# psoc6a2m register map
Vendor: Cypress Semiconductor; Series: psoc6a2m; File version: 1.0
CPU: CM4 r0p1, little endian, MPU, FPU, VTOR, 3 interrupt priority bits
Registers are 32-bit, read-write, reset 0x0 unless marked. A register's access mark holds for its fields unless they carry their own. Offsets are from the block's base; [hi:lo] are bit positions; lines under a group give offsets from that group; {n}, {i} and the like mark numbered series; 'fields as' and 'values as' point back to an identical list; <NAME> marks a mode.

## SRSS — SRSS Core Registers
Base 0x40260000
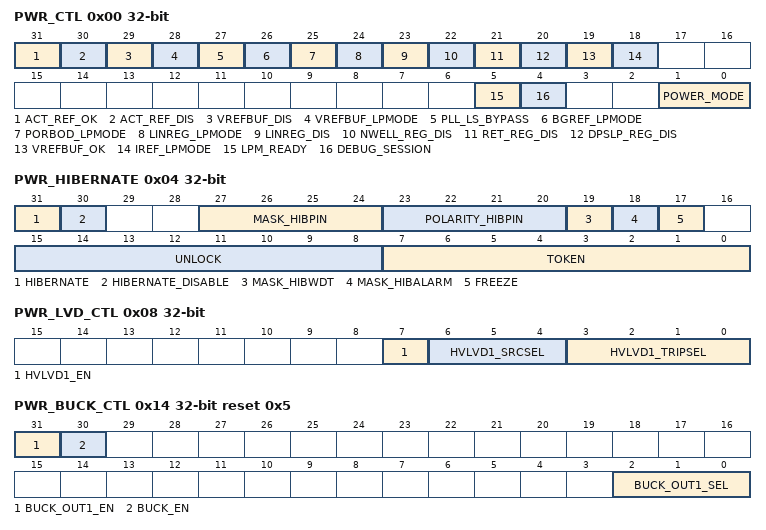
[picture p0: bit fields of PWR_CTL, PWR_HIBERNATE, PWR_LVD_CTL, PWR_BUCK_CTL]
0x00 PWR_CTL — Power Mode Control
  [31] ACT_REF_OK ro — Indicates that the normal mode of the Active Reference is ready.
  [30] ACT_REF_DIS — Disables the Active Reference. Firmware must ensure that LPM_READY==1 and BGREF_LPMODE==1 for at least 1us before disabling the Active Reference. When enabling the Active Reference, use ACT_REF_OK indicator to know when it is ready. This register is only reset by XRES/POR/BOD/OVP/HIBERNATE. 0: Active Reference is enabled 1: Active Reference is disabled
  [29] VREFBUF_DIS — Disable the 800mV voltage reference buffer. Firmware should only disable the buffer when there is no connected circuit that is using it. SRSS circuits that require it are the PLL and ECO. A particular product may have circuits outside the SRSS that use the buffer. This register is only reset by XRES/POR/BOD/OVP/HIBERNATE.
  [28] VREFBUF_LPMODE — Control the power mode of the 800mV voltage reference buffer. The value in this register is ignored and normal mode is used until LPM_READY==1. 0: ULP Voltage Reference Buffer operates in normal mode. They work for vddd ramp rates of 100mV/us or less. This register is only reset by XRES/POR/BOD/OVP/HIBERNATE. 1: ULP Voltage Reference Buffer operates in low power mode. Power supply rejection is reduced to save current, and they work for vddd ramp rates of 10mV/us or less.
  [27] PLL_LS_BYPASS — Bypass level shifter inside the PLL. 0: Do not bypass the level shifter. This setting is ok for all operational modes and vccd target voltage. 1: Bypass the level shifter. This may reduce jitter on the PLL output clock, but can only be used when vccd is targeted to 1.1V nominal. Otherwise, it can result in clock degradation and static current.
  [26] BGREF_LPMODE — Control the power mode of the ULP Bandgap Voltage and Current References. This applies to voltage and current generation and is different than the reference voltage buffer. The value in this register is ignored and normal mode is used until LPM_READY==1. When lower power mode is used, the Active Reference circuit can be disabled to reduce current. Firmware is responsible to ensure ACT_REF_OK==1 before changing back to normal mode. This register is only reset by XRES/POR/BOD/OVP/HIBERNATE. 0: ULP Active Bandgap Voltage and Current Reference operates in normal mode. They work for vddd ramp rates of 100mV/us or less. 1: ULP Active Bandgap Voltage and Current Reference operates in low power mode. Power supply rejection is reduced to save current, and they work for vddd ramp rates of 10mV/us or less. The Active Reference may be disabled using ACT_REF_DIS=0.
  [25] PORBOD_LPMODE — Control the power mode of the ULP POR/BOD circuits. The value in this register is ignored and normal mode is used until LPM_READY==1. This register is only reset by XRES/POR/BOD/OVP/HIBERNATE. 0: ULP POR/BOD circuits operate in normal mode. They work for vddd ramp rates of 100mV/us or less. 1: ULP POR/BOD circuits operate in low power mode. Response time is reduced to save current, and they work for vddd ramp rates of 10mV/us or less.
  [24] LINREG_LPMODE — Control the power mode of the ULP Linear Regulator. The value in this register is ignored and normal mode is used until LPM_READY==1. This register is only reset by XRES/POR/BOD/OVP/HIBERNATE. 0: ULP Linear Regulator operates in normal mode. Internal current consumption is 50uA and load current capability is 50mA to 300mA, depending on the number of regulator modules present in the product. 1: ULP Linear Regulator operates in low power mode. Internal current consumption is 5uA and load current capability is 25mA. Firmware must ensure the current is kept within the limit.
  [23] LINREG_DIS — Disable the linear Core Regulator. For ULP products, this is only legal when the ULP SISO-LC/SIMO-LC Buck supplies vccd, but there is no hardware protection for this case. This register is only reset by XRES/POR/BOD/OVP/HIBERNATE. 0: Linear regulator is on. 1: Linear regulator is off.
  [22] NWELL_REG_DIS — Disable the Nwell regulator. For ULP products, this is only legal when the ULP SISO-LC/SIMO-LC Buck supplies vccd, but there is no hardware protection for this case. This register is only reset by XRES/POR/BOD/OVP/HIBERNATE. 0: Nwell Regulator is on. 1: Nwell Regulator is off.
  [21] RET_REG_DIS — Disable the Retention regulator. For ULP products, this is only legal when the ULP SISO-LC/SIMO-LC Buck supplies vccd, but there is no hardware protection for this case. This register is only reset by XRES/POR/BOD/OVP/HIBERNATE. 0: Retention Regulator is on. 1: Retention Regulator is off.
  [20] DPSLP_REG_DIS — Disable the DeepSleep regulator. For ULP products, this is only legal when the ULP SISO-LC/SIMO-LC Buck supplies vccd, but there is no hardware protection for this case. This register is only reset by XRES/POR/BOD/OVP/HIBERNATE. 0: DeepSleep Regulator is on. 1: DeepSleep Regulator is off.
  [19] VREFBUF_OK ro — Indicates that the voltage reference buffer is ready. Due to synchronization delays, it may take two IMO clock cycles for hardware to clear this bit after asserting VREFBUF_DIS=1.
  [18] IREF_LPMODE — Control the power mode of the reference current generator. The value in this register is ignored and normal mode is used until LPM_READY==1. This register is only reset by XRES/POR/BOD/OVP/HIBERNATE. 0: Current reference generator operates in normal mode. It works for vddd ramp rates of 100mV/us or less. 1: Current reference generator operates in low power mode. Response time is reduced to save current, and it works for vddd ramp rates of 10mV/us or less.
  [5] LPM_READY ro — Indicates whether certain low power functions are ready. The low current circuits take longer to startup after POR/XRES/BOD/HIBERNATE wakeup than the normal mode circuits. HIBERNATE mode may be entered regardless of this bit. This register is only reset by XRES/POR/BOD/OVP/HIBERNATE. 0: If a low power circuit operation is requested, it will stay in its normal operating mode until it is ready. If DEEPSLEEP is requested by all processors WFI/WFE, the device will instead enter SLEEP. When low power circuits are ready, device will automatically enter the originally requested mode. 1: Normal operation. DEEPSLEEP and low power circuits operate as requested in other registers.
  [4] DEBUG_SESSION ro — Indicates whether a debug session is active (CDBGPWRUPREQ signal is 1)
    0=NO_SESSION (No debug session active); 1=SESSION_ACTIVE (Debug session is active. Power modes behave differently to keep the debug session active.)
  [1:0] POWER_MODE ro — Current power mode of the device. LPACTIVE/LPSLEEP are implemented as firmware configuration of multiple registers and are reported here as ACTIVE/SLEEP, respectively. Note that this field cannot be read in all power modes on actual silicon.
    0=RESET (System is resetting.); 1=ACTIVE (At least one CPU is running.); 2=SLEEP (No CPUs are running. Peripherals may be running.); 3=DEEPSLEEP (Main high-frequency clock is off; low speed clocks are available. Communication interface clocks may be present.)
0x04 PWR_HIBERNATE — HIBERNATE Mode Register
  [31] HIBERNATE — Firmware sets this bit to enter HIBERNATE mode. The system will enter HIBERNATE mode immediately after writing to this bit and will wakeup only in response to XRES or WAKEUP event. Both UNLOCK and FREEZE must have been set correctly in a previous write operations. Otherwise, it will not enter HIBERNATE. External supplies must have been stable for 250us before entering HIBERNATE mode.
  [30] HIBERNATE_DISABLE — Hibernate disable bit. 0: Normal operation, HIBERNATE works as described 1: Further writes to this register are ignored Note: This bit is a write-once bit until the next reset. Avoid changing any other bits in this register while disabling HIBERNATE mode. Also, it is recommended to clear the UNLOCK code, if it was previously written..
  [27:24] MASK_HIBPIN — When set, HIBERNATE will wakeup if the corresponding pin input matches the POLARITY_HIBPIN setting. Each bit corresponds to one of the wakeup pins.
  [23:20] POLARITY_HIBPIN — Each bit sets the active polarity of the corresponding wakeup pin. 0: Pin input of 0 will wakeup the part from HIBERNATE 1: Pin input of 1 will wakeup the part from HIBERNATE
  [19] MASK_HIBWDT — When set, HIBERNATE will wakeup if WDT matches
  [18] MASK_HIBALARM — When set, HIBERNATE will wakeup for a RTC interrupt
  [17] FREEZE — Firmware sets this bit to freeze the configuration, mode and state of all GPIOs and SIOs in the system. When entering HIBERNATE mode, the first write instructs DEEPSLEEP peripherals that they cannot ignore the upcoming freeze command. This occurs even in the illegal condition where UNLOCK is not set. If UNLOCK and HIBERNATE are properly set, the IOs actually freeze on the second write.
  [15:8] UNLOCK — This byte must be set to 0x3A for FREEZE or HIBERNATE fields to operate. Any other value in this register will cause FREEZE/HIBERNATE to have no effect, except as noted in the FREEZE description.
  [7:0] TOKEN — Contains a 8-bit token that is retained through a HIBERNATE/WAKEUP sequence that can be used by firmware to differentiate WAKEUP from a general RESET event. Note that waking up from HIBERNATE using XRES will reset this register.
0x08 PWR_LVD_CTL — Low Voltage Detector (LVD) Configuration Register
  [7] HVLVD1_EN — Enable HVLVD1 voltage monitor. When the LVD is enabled, it takes 20us for it to settle. There is no hardware stabilization counter, and it may falsely trigger during settling. It is recommended that firmware keep the interrupt masked for at least 8us, write a 1'b1 to the corresponding SRSS_INTR field to any falsely pended interrupt, and then optionally unmask the interrupt. After enabling, it further recommended to read the realted PWR_LVD_STATUS field, since the interrupt only triggers on edges. This bit is cleared (LVD is disabled) when entering DEEPSLEEP to prevent false interrupts during wakeup.
  [6:4] HVLVD1_SRCSEL — Source selection for HVLVD1
    0=VDDD (Select VDDD); 1=AMUXBUSA (Select AMUXBUSA (VDDD branch)); 2=RSVD (N/A); 3=VDDIO (N/A); 4=AMUXBUSB (Select AMUXBUSB (VDDD branch))
  [3:0] HVLVD1_TRIPSEL — Threshold selection for HVLVD1. Disable the LVD (HVLVD1_EN=0) before changing the threshold. 0: rise=1.225V (nom), fall=1.2V (nom) 1: rise=1.425V (nom), fall=1.4V (nom) 2: rise=1.625V (nom), fall=1.6V (nom) 3: rise=1.825V (nom), fall=1.8V (nom) 4: rise=2.025V (nom), fall=2V (nom) 5: rise=2.125V (nom), fall=2.1V (nom) 6: rise=2.225V (nom), fall=2.2V (nom) 7: rise=2.325V (nom), fall=2.3V (nom) 8: rise=2.425V (nom), fall=2.4V (nom) 9: rise=2.525V (nom), fall=2.5V (nom) 10: rise=2.625V (nom), fall=2.6V (nom) 11: rise=2.725V (nom), fall=2.7V (nom) 12: rise=2.825V (nom), fall=2.8V (nom) 13: rise=2.925V (nom), fall=2.9V (nom) 14: rise=3.025V (nom), fall=3.0V (nom) 15: rise=3.125V (nom), fall=3.1V (nom)
0x14 PWR_BUCK_CTL reset 0x5 — Buck Control Register
  [31] BUCK_OUT1_EN — Enable for vccbuck1 output. The value in this register is ignored unless PWR_BUCK_CTL.BUCK_EN==1. This register is only reset by XRES/POR/BOD/OVP/HIBERNATE. The regulator takes up to 600us to charge the external capacitor. If there is additional load current while charging, this will increase the startup time. The SAS specifies the required sequence when transitioning vccd from the LDO to SIMO Buck output #1.
  [30] BUCK_EN — Master enable for buck converter. This register is only reset by XRES/POR/BOD/OVP/HIBERNATE.
  [2:0] BUCK_OUT1_SEL — Voltage output selection for vccbuck1 output. This register is only reset by XRES/POR/BOD/OVP/HIBERNATE. When increasing the voltage, it can take up to 200us for the output voltage to settle. When decreasing the voltage, the settling time depends on the load current. 0: 0.85V 1: 0.875V 2: 0.90V 3: 0.95V 4: 1.05V 5: 1.10V 6: 1.15V 7: 1.20V
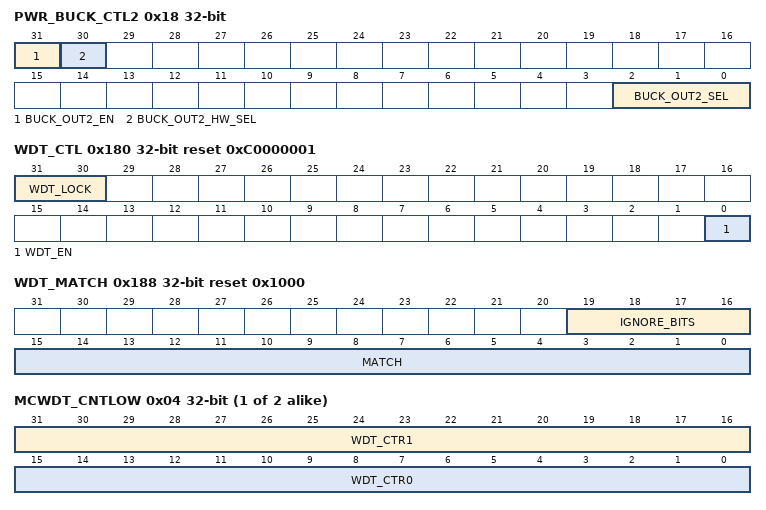
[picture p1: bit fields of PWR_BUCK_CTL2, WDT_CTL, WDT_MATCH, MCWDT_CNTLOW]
0x18 PWR_BUCK_CTL2 — Buck Control Register 2
  [31] BUCK_OUT2_EN — Enable for vccbuck2 output. The value in this register is ignored unless PWR_BUCK_CTL.BUCK_EN==1. The regulator takes up to 600us to charge the external capacitor. If there is additional load current while charging, this will increase the startup time.
  [30] BUCK_OUT2_HW_SEL — Hardware control for vccbuck2 output. When this bit is set, the value in BUCK_OUT2_EN is ignored and a hardware signal is used instead. If the product has supporting hardware, it can directly control the enable signal for vccbuck2. The same charging time in BUCK_OUT2_EN applies.
  [2:0] BUCK_OUT2_SEL — Voltage output selection for vccbuck2 output. When increasing the voltage, it can take up to 200us for the output voltage to settle. When decreasing the voltage, the settling time depends on the load current. 0: 1.15V 1: 1.20V 2: 1.25V 3: 1.30V 4: 1.35V 5: 1.40V 6: 1.45V 7: 1.50V
0x1C PWR_LVD_STATUS ro — Low Voltage Detector (LVD) Status Register
  [0] HVLVD1_OK — HVLVD1 output. 0: below voltage threshold 1: above voltage threshold
{0x80+4i} PWR_HIB_DATA[{i}] (i=0..15) — HIBERNATE Data Register
  [31:0] HIB_DATA — Additional data that is retained through a HIBERNATE/WAKEUP sequence that can be used by firmware for any application-specific purpose. Note that waking up from HIBERNATE using XRES will reset this register.
0x180 WDT_CTL reset 0xC0000001 — Watchdog Counter Control Register
  [31:30] WDT_LOCK — Prohibits writing to WDT_*, CLK_ILO_CONFIG, CLK_SELECT.LFCLK_SEL, and CLK_TRIM_ILO_CTL registers when not equal 0. Requires at least two different writes to unlock. A change in WDT_LOCK takes effect beginning with the next write cycle. Note that this field is 2 bits to force multiple writes only. It represents only a single write protect signal protecting all those registers at the same time. WDT will lock on any reset. This field is not retained during DEEPSLEEP or HIBERNATE mode, so the WDT will be locked after wakeup from these modes.
    0=NO_CHG (No effect); 1=CLR0 (Clears bit 0); 2=CLR1 (Clears bit 1); 3=SET01 (Sets both bits 0 and 1)
  [0] WDT_EN — Enable this watchdog timer. This field is retained during DEEPSLEEP and HIBERNATE modes.
0x184 WDT_CNT — Watchdog Counter Count Register
  [15:0] COUNTER — Current value of WDT Counter. The write feature of this register is for engineering use (DfV), have no synchronization, and can only be applied when the WDT is fully off. When writing, the value is updated immediately in the WDT counter, but it will read back as the old value until this register resynchronizes just after the negedge of ILO. Writes will be ignored if they occur when the WDT is enabled.
0x188 WDT_MATCH reset 0x1000 — Watchdog Counter Match Register
  [19:16] IGNORE_BITS — The number of MSB bits of the watchdog timer that are NOT checked against MATCH. This value provides control over the time-to-reset of the watchdog (which happens after 3 successive matches). Up to 12 MSB can be ignored. Settings >12 behave like a setting of 12.
  [15:0] MATCH — Match value for Watchdog counter. Every time WDT_COUNTER reaches MATCH an interrupt is generated. Two unserviced interrupts will lead to a system reset (i.e. at the third match).
{0x200+0x40*i} MCWDT_STRUCT[{i}] (i=0..1) group — Multi-Counter Watchdog Timer
  0x04 MCWDT_CNTLOW — Multi-Counter Watchdog Sub-counters 0/1
    [31:16] WDT_CTR1 — Current value of sub-counter 1 for this MCWDT. Software writes are ignored when the sub-counter is enabled
    [15:0] WDT_CTR0 — Current value of sub-counter 0 for this MCWDT. Software writes are ignored when the sub-counter is enabled.
  0x08 MCWDT_CNTHIGH — Multi-Counter Watchdog Sub-counter 2
    [31:0] WDT_CTR2 — Current value of sub-counter 2 for this MCWDT. Software writes are ignored when the sub-counter is enabled
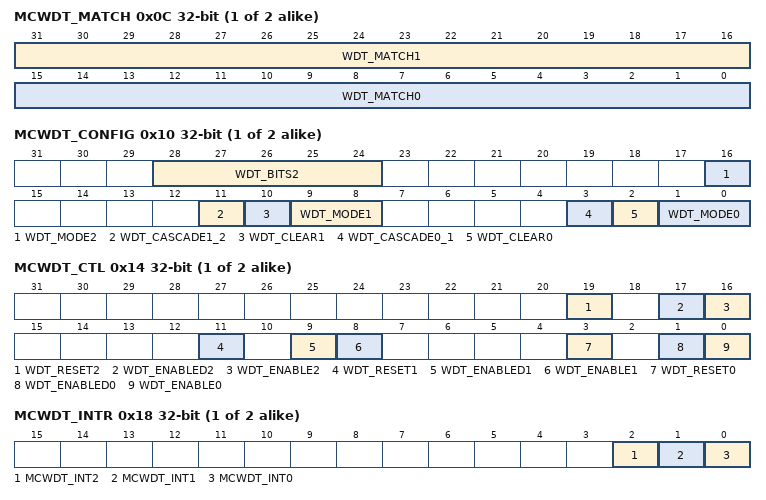
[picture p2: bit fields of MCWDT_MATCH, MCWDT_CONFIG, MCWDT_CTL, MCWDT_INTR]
  0x0C MCWDT_MATCH — Multi-Counter Watchdog Counter Match Register
    [31:16] WDT_MATCH1 — Match value for sub-counter 1 of this MCWDT
    [15:0] WDT_MATCH0 — Match value for sub-counter 0 of this MCWDT
  0x10 MCWDT_CONFIG — Multi-Counter Watchdog Counter Configuration
    [28:24] WDT_BITS2 — Bit to observe for WDT_INT2: 0: Assert after bit0 of WDT_CTR2 toggles (one int every tick) .. 31: Assert after bit31 of WDT_CTR2 toggles (one int every 2^31 ticks)
    [16] WDT_MODE2 — Watchdog Counter 2 Mode.
      0=NOTHING (Free running counter with no interrupt requests); 1=INT (Free running counter with interrupt request that occurs one LFCLK cycle after the specified bit in CTR2 toggles (see WDT_BITS2).)
    [11] WDT_CASCADE1_2 — Cascade Watchdog Counters 1,2. Counter 2 increments the cycle after WDT_CTR1=WDT_MATCH1. It is allowed to cascade all three WDT counters. 0: Independent counters 1: Cascaded counters. When cascading all three counters, WDT_CLEAR1 must be 1.
    [10] WDT_CLEAR1 — Clear Watchdog Counter when WDT_CTR1==WDT_MATCH1. In other words WDT_CTR1 divides LFCLK by (WDT_MATCH1+1). 0: Free running counter 1: Clear on match. In this mode, the minimum legal setting of WDT_MATCH1 is 1.
    [9:8] WDT_MODE1 — Watchdog Counter Action on Match. Action is taken on the next increment after the values match (WDT_CTR1=WDT_MATCH1).
      0=NOTHING (Do nothing); 1=INT (Assert WDT_INTx); 2=RESET (Assert WDT Reset); 3=INT_THEN_RESET (Assert WDT_INTx, assert WDT Reset after 3rd unhandled interrupt)
    [3] WDT_CASCADE0_1 — Cascade Watchdog Counters 0,1. Counter 1 increments the cycle after WDT_CTR0=WDT_MATCH0. 0: Independent counters 1: Cascaded counters
    [2] WDT_CLEAR0 — Clear Watchdog Counter when WDT_CTR0=WDT_MATCH0. In other words WDT_CTR0 divides LFCLK by (WDT_MATCH0+1). 0: Free running counter 1: Clear on match. In this mode, the minimum legal setting of WDT_MATCH0 is 1.
    [1:0] WDT_MODE0 — Watchdog Counter Action on Match. Action is taken on the next increment after the values match (WDT_CTR0=WDT_MATCH0).
      values as WDT_MODE1
  0x14 MCWDT_CTL — Multi-Counter Watchdog Counter Control
    [19] WDT_RESET2 — Resets counter 0 back to 0000. Hardware will reset this bit after counter was reset. This will take up to one LFCLK cycle to take effect.
    [17] WDT_ENABLED2 ro — Indicates actual state of counter. May lag WDT_ENABLE2 by up to two LFCLK cycles.
    [16] WDT_ENABLE2 — Enable subcounter 2. May take up to 2 LFCLK cycles to take effect. 0: Counter is disabled (not clocked) 1: Counter is enabled (counting up)
    [11] WDT_RESET1 — Resets counter 0 back to 0000. Hardware will reset this bit after counter was reset. This will take up to one LFCLK cycle to take effect.
    [9] WDT_ENABLED1 ro — Indicates actual state of counter. May lag WDT_ENABLE1 by up to two LFCLK cycles.
    [8] WDT_ENABLE1 — Enable subcounter 1. May take up to 2 LFCLK cycles to take effect. 0: Counter is disabled (not clocked) 1: Counter is enabled (counting up)
    [3] WDT_RESET0 — Resets counter 0 back to 0000. Hardware will reset this bit after counter was reset. This will take up to one LFCLK cycle to take effect.
    [1] WDT_ENABLED0 ro — Indicates actual state of counter. May lag WDT_ENABLE0 by up to two LFCLK cycles.
    [0] WDT_ENABLE0 — Enable subcounter 0. May take up to 2 LFCLK cycles to take effect. 0: Counter is disabled (not clocked) 1: Counter is enabled (counting up)
  0x18 MCWDT_INTR — Multi-Counter Watchdog Counter Interrupt Register
    [2] MCWDT_INT2 — MCWDT Interrupt Request for sub-counter 2. This bit is set by hardware as configured by this registers. This bit must be cleared by firmware. Clearing this bit also prevents Reset from happening when WDT_MODE2=3.
    [1] MCWDT_INT1 — MCWDT Interrupt Request for sub-counter 1. This bit is set by hardware as configured by this registers. This bit must be cleared by firmware. Clearing this bit also prevents Reset from happening when WDT_MODE1=3.
    [0] MCWDT_INT0 — MCWDT Interrupt Request for sub-counter 0. This bit is set by hardware as configured by this registers. This bit must be cleared by firmware. Clearing this bit also prevents Reset from happening when WDT_MODE0=3.
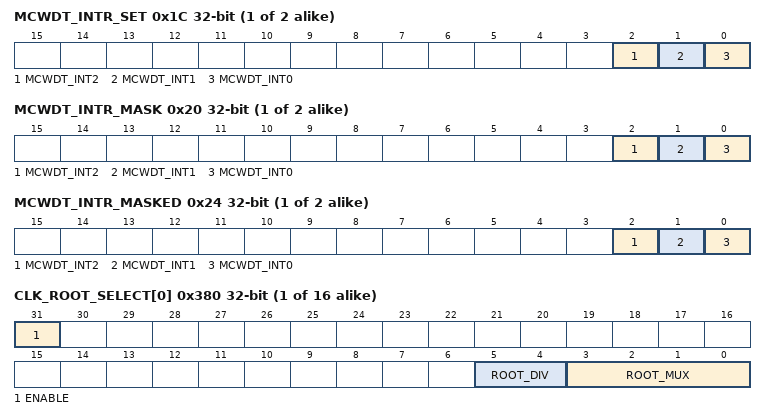
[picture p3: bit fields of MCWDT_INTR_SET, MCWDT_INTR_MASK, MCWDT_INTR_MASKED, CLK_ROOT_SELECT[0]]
  0x1C MCWDT_INTR_SET — Multi-Counter Watchdog Counter Interrupt Set Register
    [2] MCWDT_INT2 — Set interrupt for MCWDT_INT2
    [1] MCWDT_INT1 — Set interrupt for MCWDT_INT1
    [0] MCWDT_INT0 — Set interrupt for MCWDT_INT0
  0x20 MCWDT_INTR_MASK — Multi-Counter Watchdog Counter Interrupt Mask Register
    [2] MCWDT_INT2 — Mask for sub-counter 2
    [1] MCWDT_INT1 — Mask for sub-counter 1
    [0] MCWDT_INT0 — Mask for sub-counter 0
  0x24 MCWDT_INTR_MASKED ro — Multi-Counter Watchdog Counter Interrupt Masked Register
    [2] MCWDT_INT2 — Logical and of corresponding request and mask bits.
    [1] MCWDT_INT1 — Logical and of corresponding request and mask bits.
    [0] MCWDT_INT0 — Logical and of corresponding request and mask bits.
  0x28 MCWDT_LOCK — Multi-Counter Watchdog Counter Lock Register
    [31:30] MCWDT_LOCK — Prohibits writing control and configuration registers related to this MCWDT when not equal 0 (as specified in the other register descriptions). Requires at least two different writes to unlock. Note that this field is 2 bits to force multiple writes only. Each MCWDT has a separate local lock. LFCLK settings are locked by the global WDT_LOCK register, and this register has no effect on that.
      values as WDT_CTL.WDT_LOCK
{0x300+4i} CLK_DSI_SELECT[{i}] (i=0..15) — Clock DSI Select Register
  [4:0] DSI_MUX — Selects a DSI source or low frequency clock for use in a clock path. The output of this mux can be selected for clock PATH<i> using CLK_SELECT_PATH register. Using the output of this mux as HFCLK source will result in undefined behavior. It can be used to clocks to DSI or to the reference inputs of FLL/PLL, subject to the frequency limits of those circuits. This mux is not glitch free, so do not change the selection while it is an actively selected clock.
    {v}=DSI_OUT{v} (DSI{v} - dsi_out[{v}]) (v=0..15); 16=ILO (ILO - Internal Low-speed Oscillator); 17=WCO (WCO - Watch-Crystal Oscillator); 18=ALTLF (ALTLF - Alternate Low-Frequency Clock); 19=PILO (PILO - Precision Internal Low-speed Oscillator)
{0x340+4i} CLK_PATH_SELECT[{i}] (i=0..15) — Clock Path Select Register
  [2:0] PATH_MUX — Selects a source for clock PATH<i>. Note that not all products support all clock sources. Selecting a clock source that is not supported will result in undefined behavior.
    0=IMO (IMO - Internal R/C Oscillator); 1=EXTCLK (EXTCLK - External Clock Pin); 2=ECO (ECO - External-Crystal Oscillator); 3=ALTHF (ALTHF - Alternate High-Frequency clock input (product-specific clock)); 4=DSI_MUX (DSI_MUX - Output of DSI mux for this path. Using a DSI source directly as root of HFCLK will result in undefined behavior.)
{0x380+4i} CLK_ROOT_SELECT[{i}] (i=0..15) — Clock Root Select Register
  [31] ENABLE — Enable for this clock root. All clock roots default to disabled (ENABLE==0) except HFCLK0, which cannot be disabled.
  [5:4] ROOT_DIV — Selects predivider value for this clock root and DSI input.
    0=NO_DIV (Transparent mode, feed through selected clock source w/o dividing.); 1=DIV_BY_2 (Divide selected clock source by 2); 2=DIV_BY_4 (Divide selected clock source by 4); 3=DIV_BY_8 (Divide selected clock source by 8)
  [3:0] ROOT_MUX — Selects a clock path as the root of HFCLK<k> and for SRSS DSI input <k>. Use CLK_SELECT_PATH[i] to configure the desired path. Some paths may have FLL or PLL available (product-specific), and the control and bypass mux selections of these are in other registers. Configure the FLL using CLK_FLL_CONFIG register. Configure a PLL using the related CLK_PLL_CONFIG[k] register. Note that not all products support all clock sources. Selecting a clock source that is not supported will result in undefined behavior.
    0=PATH0 (Select PATH0 (can be configured for FLL)); {v}=PATH{v} (Select PATH{v} (can be configured for PLL{v-1}, if available in the product)) (v=1..15)
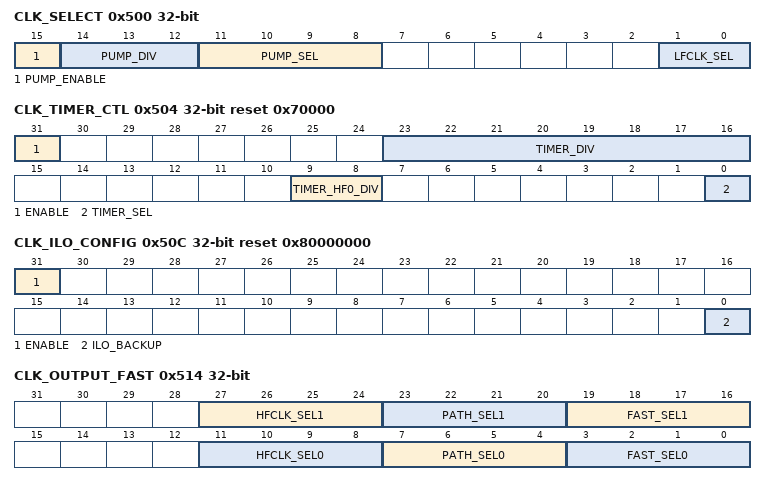
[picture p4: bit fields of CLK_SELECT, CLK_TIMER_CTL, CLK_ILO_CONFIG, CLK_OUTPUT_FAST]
0x500 CLK_SELECT — Clock selection register
  [15] PUMP_ENABLE — Enable the pump clock. PUMP_ENABLE and the PUMP_SEL mux are not glitch-free to minimize side-effects, avoid changing the PUMP_SEL and PUMP_DIV while changing PUMP_ENABLE. To change the settings, do the following: 1) If the pump clock is enabled, write PUMP_ENABLE=0 without changing PUMP_SEL and PUMP_DIV. 2) Change PUMP_SEL and PUMP_DIV to desired settings with PUMP_ENABLE=0. 3) Write PUMP_ENABLE=1 without changing PUMP_SEL and PUMP_DIV.
  [14:12] PUMP_DIV — Division ratio for PUMPCLK. Uses selected PUMP_SEL clock as the source.
    0=NO_DIV (Transparent mode, feed through selected clock source w/o dividing.); 1=DIV_BY_2 (Divide selected clock source by 2); 2=DIV_BY_4 (Divide selected clock source by 4); 3=DIV_BY_8 (Divide selected clock source by 8); 4=DIV_BY_16 (Divide selected clock source by 16)
  [11:8] PUMP_SEL — Selects clock PATH<k>, where k=PUMP_SEL. The output of this mux goes to the PUMP_DIV to make PUMPCLK Each product has a specific number of available clock paths. Selecting a path that is not implemented on a product will result in undefined behavior. Note that this is not a glitch free mux.
  [1:0] LFCLK_SEL — Select source for LFCLK. Note that not all products support all clock sources. Selecting a clock source that is not supported will result in undefined behavior. Writes to this field are ignored unless the WDT is unlocked using WDT_LOCK register.
    0=ILO (ILO - Internal Low-speed Oscillator); 1=WCO (WCO - Watch-Crystal Oscillator. Requires Backup domain to be present and properly configured (including external watch crystal, if used).); 2=ALTLF (ALTLF - Alternate Low-Frequency Clock. Capability is product-specific); 3=PILO (PILO - Precision ILO. If present, it works in DEEPSLEEP and higher modes. Does not work in HIBERNATE mode.)
0x504 CLK_TIMER_CTL reset 0x70000 — Timer Clock Control Register
  [31] ENABLE — Enable for TIMERCLK. 0: TIMERCLK is off 1: TIMERCLK is enabled
  [23:16] TIMER_DIV — Divide selected timer clock source by (1+TIMER_DIV). The output of this divider is TIMERCLK Allows for integer divisions in the range [1, 256]. Do not change this setting while the timer is enabled.
  [9:8] TIMER_HF0_DIV — Predivider used when HF0_DIV is selected in TIMER_SEL. If HFCLK0 frequency is less than 100MHz and has approximately 50 percent duty cycle, then no division is required (NO_DIV). Otherwise, select a divide ratio of 2, 4, or 8 before selected HF0_DIV as the timer clock.
    0=NO_DIV (Transparent mode, feed through selected clock source w/o dividing or correcting duty cycle.); 1=DIV_BY_2 (Divide HFCLK0 by 2.); 2=DIV_BY_4 (Divide HFCLK0 by 4.); 3=DIV_BY_8 (Divide HFCLK0 by 8.)
  [0] TIMER_SEL — Select source for TIMERCLK. The output of this mux can be further divided using TIMER_DIV.
    0=IMO (IMO - Internal Main Oscillator); 1=HF0_DIV (Select the output of the predivider configured by TIMER_HF0_DIV.)
0x50C CLK_ILO_CONFIG reset 0x80000000 — ILO Configuration
  [31] ENABLE — Master enable for ILO. Writes to this field are ignored unless the WDT is unlocked using WDT_LOCK register.
  [0] ILO_BACKUP — If backup domain is present on this product, this register indicates that ILO should stay enabled for use by backup domain during XRES, HIBERNATE mode, and through power-related resets like BOD on VDDD/VCCD. Writes to this field are ignored unless the WDT is unlocked using WDT_LOCK register. 0: ILO turns off at XRES/BOD event or HIBERNATE entry. 1: ILO remains on if backup domain is present and powered even for XRES/BOD or HIBERNATE entry.
0x510 CLK_IMO_CONFIG reset 0x80000000 — IMO Configuration
  [31] ENABLE — Master enable for IMO oscillator. This bit must be high at all times for all functions to work properly. Hardware will automatically disable the IMO during DEEPSLEEP, HIBERNATE, and XRES.
0x514 CLK_OUTPUT_FAST — Fast Clock Output Select Register
  [27:24] HFCLK_SEL1 — Selects a HFCLK tree for use in fast clock output #1 logic
  [23:20] PATH_SEL1 — Selects a clock path to use in fast clock output #1 logic. For FLL path, it connects after the bypass mux. For PLL path(s), it connects after the CLK_PLL_DDFT mux. 1-15: PLL output on path1-path15 (if available)
  [19:16] FAST_SEL1 — Select signal for fast clock output #1
    0=NC (Disabled - output is 0. For power savings, clocks are blocked before entering any muxes, including PATH_SEL1 and HFCLK_SEL1.); 1=ECO (External Crystal Oscillator (ECO)); 2=EXTCLK (External clock input (EXTCLK)); 3=ALTHF (Alternate High-Frequency (ALTHF) clock input to SRSS); 4=TIMERCLK (Timer clock. It is grouped with the fast clocks because it may be a gated version of a fast clock, and therefore may have a short high pulse.); 5=PATH_SEL1 (Selects the clock path chosen by PATH_SEL1 field); 6=HFCLK_SEL1 (Selects the output of the HFCLK_SEL1 mux); 7=SLOW_SEL1 (Selects the output of CLK_OUTPUT_SLOW.SLOW_SEL1)
  [11:8] HFCLK_SEL0 — Selects a HFCLK tree for use in fast clock output #0
  [7:4] PATH_SEL0 — Selects a clock path to use in fast clock output #0 logic. For FLL path, it connects after the bypass mux. For PLL path(s), it connects after the CLK_PLL_DDFT mux. 0: FLL output 1-15: PLL output on path1-path15 (if available)
  [3:0] FAST_SEL0 — Select signal for fast clock output #0
    0=NC (Disabled - output is 0. For power savings, clocks are blocked before entering any muxes, including PATH_SEL0 and HFCLK_SEL0.); 1=ECO (External Crystal Oscillator (ECO)); 2=EXTCLK (External clock input (EXTCLK)); 3=ALTHF (Alternate High-Frequency (ALTHF) clock input to SRSS); 4=TIMERCLK (Timer clock. It is grouped with the fast clocks because it may be a gated version of a fast clock, and therefore may have a short high pulse.); 5=PATH_SEL0 (Selects the clock path chosen by PATH_SEL0 field); 6=HFCLK_SEL0 (Selects the output of the HFCLK_SEL0 mux); 7=SLOW_SEL0 (Selects the output of CLK_OUTPUT_SLOW.SLOW_SEL0)
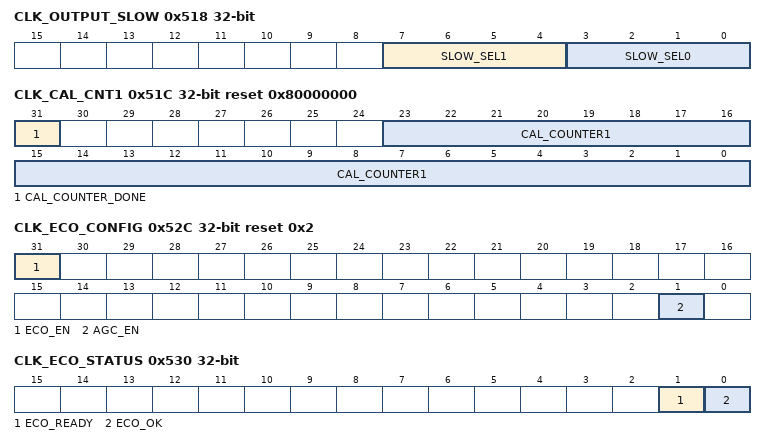
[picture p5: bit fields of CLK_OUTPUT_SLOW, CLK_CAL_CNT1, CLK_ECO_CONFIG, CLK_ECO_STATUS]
0x518 CLK_OUTPUT_SLOW — Slow Clock Output Select Register
  [7:4] SLOW_SEL1 — Select signal for slow clock output #1
    0=NC (Disabled - output is 0. For power savings, clocks are blocked before entering any muxes.); 1=ILO (Internal Low Speed Oscillator (ILO)); 2=WCO (Watch-Crystal Oscillator (WCO)); 3=BAK (Root of the Backup domain clock tree (BAK)); 4=ALTLF (Alternate low-frequency clock input to SRSS (ALTLF)); 5=LFCLK (Root of the low-speed clock tree (LFCLK)); 6=IMO (Internal Main Oscillator (IMO). This is grouped with the slow clocks so it can be observed during DEEPSLEEP entry/exit.); 7=SLPCTRL (Sleep Controller clock (SLPCTRL). This is grouped with the slow clocks so it can be observed during DEEPSLEEP entry/exit.); 8=PILO (Precision Internal Low Speed Oscillator (PILO))
  [3:0] SLOW_SEL0 — Select signal for slow clock output #0
    values as SLOW_SEL1
0x51C CLK_CAL_CNT1 reset 0x80000000 — Clock Calibration Counter 1
  [31] CAL_COUNTER_DONE ro — Status bit indicating that the internal counter #1 is finished counting and CLK_CAL_CNT2.COUNTER stopped counting up
  [23:0] CAL_COUNTER1 — Down-counter clocked on fast DDFT output #0 (see TST_DDFT_FAST_CTL). This register always reads as zero. Counting starts internally when this register is written with a nonzero value. CAL_COUNTER_DONE goes immediately low to indicate that the counter has started and will be asserted when the counters are done. Do not write this field unless CAL_COUNTER_DONE==1.
0x520 CLK_CAL_CNT2 ro — Clock Calibration Counter 2
  [23:0] CAL_COUNTER2 — Up-counter clocked on fast DDFT output #1 (see TST_DDFT_FAST_CTL). When CLK_CAL_CNT1.CAL_COUNTER_DONE==1, the counter is stopped and can be read by SW. Do not read this value unless CAL_COUNTER_DONE==1. The expected final value is related to the ratio of clock frequencies used for the two counters and the value loaded into counter 1: CLK_CAL_CNT2.COUNTER=(F_cnt2/F_cnt1)*(CLK_CAL_CNT1.COUNTER)
0x52C CLK_ECO_CONFIG reset 0x2 — ECO Configuration Register
  [31] ECO_EN — Master enable for ECO oscillator.
  [1] AGC_EN — Automatic Gain Control (AGC) enable. When set, the oscillation amplitude is controlled to the level selected by ECO_TRIM0.ATRIM. When low, the amplitude is not explicitly controlled and will grow until it saturates to the supply rail (1.8V nom). WARNING: use care when disabling AGC because driving a crystal beyond its rated limit can permanently damage the crystal.
0x530 CLK_ECO_STATUS ro — ECO Status Register
  [1] ECO_READY — Indicates the ECO internal oscillator circuit has fully stabilized.
  [0] ECO_OK — Indicates the ECO internal oscillator circuit has sufficient amplitude. It may not meet the PPM accuracy or duty cycle spec.
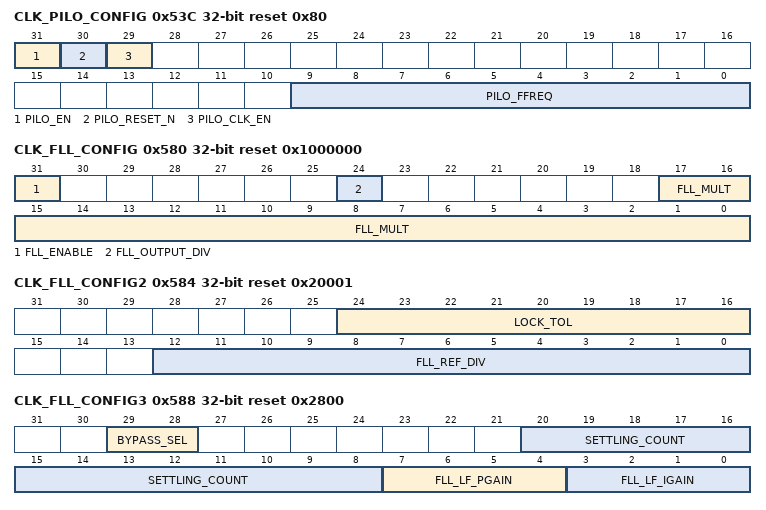
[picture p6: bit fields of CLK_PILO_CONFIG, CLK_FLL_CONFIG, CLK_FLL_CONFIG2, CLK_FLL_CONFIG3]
0x53C CLK_PILO_CONFIG reset 0x80 — Precision ILO Configuration Register
  [31] PILO_EN — Enable PILO. When enabling PILO, set PILO_EN=1, wait 1ms, then PILO_RESET_N=1 and PILO_CLK_EN=1. When disabling PILO, clear PILO_EN=0, PILO_RESET_N=0, and PLO_CLK_EN=0 in the same write cycle.
  [30] PILO_RESET_N — Reset the PILO. See PILO_EN field for required sequencing.
  [29] PILO_CLK_EN — Enable the PILO clock output. See PILO_EN field for required sequencing.
  [9:0] PILO_FFREQ — Fine frequency trim allowing +/-250ppm accuracy with periodic calibration. The nominal step size of the LSB is 8Hz.
0x580 CLK_FLL_CONFIG reset 0x1000000 — FLL Configuration Register
  [31] FLL_ENABLE — Master enable for FLL. Do not enable until the reference clock has stabilized. 0: Block is powered off 1: Block is powered on
  [24] FLL_OUTPUT_DIV — Control bits for Output divider. Set the divide value before enabling the FLL, and do not change it while FLL is enabled. 0: no division 1: divide by 2
  [17:0] FLL_MULT — Multiplier to determine CCO frequency in multiples of the frequency of the selected reference clock (Fref). Ffll = (FLL_MULT) * (Fref / REFERENCE_DIV) / (OUTPUT_DIV+1)
0x584 CLK_FLL_CONFIG2 reset 0x20001 — FLL Configuration Register 2
  [24:16] LOCK_TOL — Lock tolerance sets the error threshold for when the FLL output is considered locked to the reference input. A high tolerance can be used to lock more quickly or to track a less accurate source. The tolerance should be set so that the FLL does not unlock under normal conditions. The tolerance is the allowed difference between the count value for the ideal formula and the measured value. 0: tolerate error of 1 count value 1: tolerate error of 2 count values ... 511: tolerate error of 512 count values
  [12:0] FLL_REF_DIV — Control bits for reference divider. Set the divide value before enabling the FLL, and do not change it while FLL is enabled. 0: illegal (undefined behavior) 1: divide by 1 ... 8191: divide by 8191
0x588 CLK_FLL_CONFIG3 reset 0x2800 — FLL Configuration Register 3
  [29:28] BYPASS_SEL — Bypass mux located just after FLL output.
    0=AUTO (Automatic using lock indicator. When unlocked, automatically selects FLL reference input (bypass mode). When locked, automatically selects FLL output.); 1=AUTO1 (Same as AUTO); 2=FLL_REF (Select FLL reference input (bypass mode). Ignores lock indicator); 3=FLL_OUT (Select FLL output. Ignores lock indicator.)
  [20:8] SETTLING_COUNT — Number of undivided reference clock cycles to wait after changing the CCO trim until the loop measurement restarts. A delay allows the CCO output to settle and gives a more accurate measurement. The default is tuned to an 8MHz reference clock since the IMO is expected to be the most common use case. 0: no settling time 1: wait one reference clock cycle ... 8191: wait 8191 reference clock cycles
  [7:4] FLL_LF_PGAIN — FLL Loop Filter Proportional Gain Setting 0: 1/256 1: 1/128 2: 1/64 3: 1/32 4: 1/16 5: 1/8 6: 1/4 7: 1/2 8: 1.0 9: 2.0 10: 4.0 11: 8.0 >=12: illegal
  [3:0] FLL_LF_IGAIN — FLL Loop Filter Integral Gain Setting 0: 1/256 1: 1/128 2: 1/64 3: 1/32 4: 1/16 5: 1/8 6: 1/4 7: 1/2 8: 1.0 9: 2.0 10: 4.0 11: 8.0 >=12: illegal
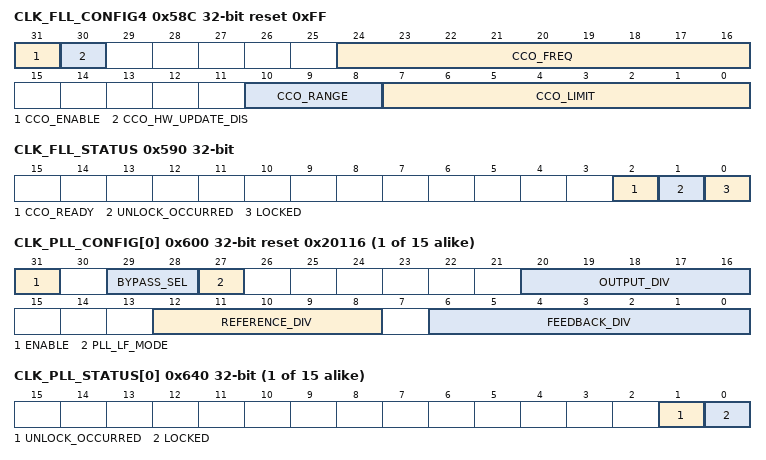
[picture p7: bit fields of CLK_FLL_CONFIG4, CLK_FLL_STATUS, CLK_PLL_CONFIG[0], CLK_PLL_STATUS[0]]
0x58C CLK_FLL_CONFIG4 reset 0xFF — FLL Configuration Register 4
  [31] CCO_ENABLE — Enable the CCO. It is required to enable the CCO before using the FLL. 0: Block is powered off 1: Block is powered on
  [30] CCO_HW_UPDATE_DIS — Disable CCO frequency update by FLL hardware 0: Hardware update of CCO settings is allowed. Use this setting for normal FLL operation. 1: Hardware update of CCO settings is disabled. Use this setting for open-loop FLL operation.
  [24:16] CCO_FREQ — CCO frequency code. This is updated by HW when the FLL is enabled. It can be manually updated to use the CCO in an open loop configuration. The meaning of each frequency code depends on the range.
  [10:8] CCO_RANGE — Frequency range of CCO
    0=RANGE0 (Target frequency is in range [48, 64) MHz); 1=RANGE1 (Target frequency is in range [64, 85) MHz); 2=RANGE2 (Target frequency is in range [85, 113) MHz); 3=RANGE3 (Target frequency is in range [113, 150) MHz); 4=RANGE4 (Target frequency is in range [150, 200] MHz)
  [7:0] CCO_LIMIT — Maximum CCO offset allowed (used to prevent FLL dynamics from selecting an CCO frequency that the logic cannot support)
0x590 CLK_FLL_STATUS — FLL Status Register
  [2] CCO_READY ro — This indicates that the CCO is internally settled and ready to use.
  [1] UNLOCK_OCCURRED
  [0] LOCKED ro — FLL Lock Indicator
{0x600+4i} CLK_PLL_CONFIG[{i}] (i=0..14) reset 0x20116 — PLL Configuration Register
  [31] ENABLE — Master enable for PLL. Setup FEEDBACK_DIV, REFERENCE_DIV, and OUTPUT_DIV at least one cycle before setting ENABLE=1. Fpll = (FEEDBACK_DIV) * (Fref / REFERENCE_DIV) / (OUTPUT_DIV) 0: Block is disabled 1: Block is enabled
  [29:28] BYPASS_SEL — Bypass mux located just after PLL output. This selection is glitch-free and can be changed while the PLL is running.
    0=AUTO (Automatic using lock indicator. When unlocked, automatically selects PLL reference input (bypass mode). When locked, automatically selects PLL output.); 1=AUTO1 (Same as AUTO); 2=PLL_REF (Select PLL reference input (bypass mode). Ignores lock indicator); 3=PLL_OUT (Select PLL output. Ignores lock indicator.)
  [27] PLL_LF_MODE — VCO frequency range selection. Configure this bit according to the targeted VCO frequency. Do not change this setting while the PLL is enabled. 0: VCO frequency is [200MHz, 400MHz] 1: VCO frequency is [170MHz, 200MHz)
  [20:16] OUTPUT_DIV — Control bits for Output divider. Set the divide value before enabling the PLL, and do not change it while PLL is enabled. 0: illegal (undefined behavior) 1: illegal (undefined behavior) 2: divide by 2. Suitable for direct usage as HFCLK source. ... 16: divide by 16. Suitable for direct usage as HFCLK source. >16: illegal (undefined behavior)
  [12:8] REFERENCE_DIV — Control bits for reference divider. Set the divide value before enabling the PLL, and do not change it while PLL is enabled. 0: illegal (undefined behavior) 1: divide by 1 ... 20: divide by 20 others: illegal (undefined behavior)
  [6:0] FEEDBACK_DIV — Control bits for feedback divider. Set the divide value before enabling the PLL, and do not change it while PLL is enabled. 0-21: illegal (undefined behavior) 22: divide by 22 ... 112: divide by 112 >112: illegal (undefined behavior)
{0x640+4i} CLK_PLL_STATUS[{i}] (i=0..14) — PLL Status Register
  [1] UNLOCK_OCCURRED — This bit sets whenever the PLL Lock bit goes low, and stays set until cleared by firmware.
  [0] LOCKED ro — PLL Lock Indicator
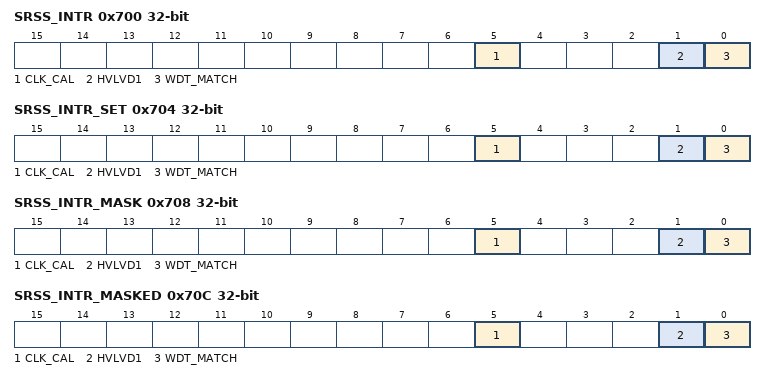
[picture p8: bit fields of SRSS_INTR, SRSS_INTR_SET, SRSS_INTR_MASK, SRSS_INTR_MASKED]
0x700 SRSS_INTR — SRSS Interrupt Register
  [5] CLK_CAL — Clock calibration counter is done
  [1] HVLVD1 — Interrupt for low voltage detector HVLVD1
  [0] WDT_MATCH — WDT Interrupt Request. This bit is set each time WDT_COUNTR==WDT_MATCH. W1C also feeds the watch dog. Missing 2 interrupts in a row will generate a reset. Due to internal synchronization, it takes 2 SYSCLK cycles to update after a W1C.
0x704 SRSS_INTR_SET — SRSS Interrupt Set Register
  [5] CLK_CAL — Set interrupt for clock calibration counter done
  [1] HVLVD1 — Set interrupt for low voltage detector HVLVD1
  [0] WDT_MATCH — Set interrupt for low voltage detector WDT_MATCH
0x708 SRSS_INTR_MASK — SRSS Interrupt Mask Register
  [5] CLK_CAL — Mask for clock calibration done
  [1] HVLVD1 — Mask for low voltage detector HVLVD1
  [0] WDT_MATCH — Mask for watchdog timer. Clearing this bit will not forward the interrupt to the CPU. It will not, however, disable the WDT reset generation on 2 missed interrupts.
0x70C SRSS_INTR_MASKED ro — SRSS Interrupt Masked Register
  [5] CLK_CAL — Logical and of corresponding request and mask bits.
  [1] HVLVD1 — Logical and of corresponding request and mask bits.
  [0] WDT_MATCH — Logical and of corresponding request and mask bits.
0x710 SRSS_INTR_CFG — SRSS Interrupt Configuration Register
  [1:0] HVLVD1_EDGE_SEL — Sets which edge(s) will trigger an IRQ for HVLVD1
    0=DISABLE (Disabled); 1=RISING (Rising edge); 2=FALLING (Falling edge); 3=BOTH (Both rising and falling edges)
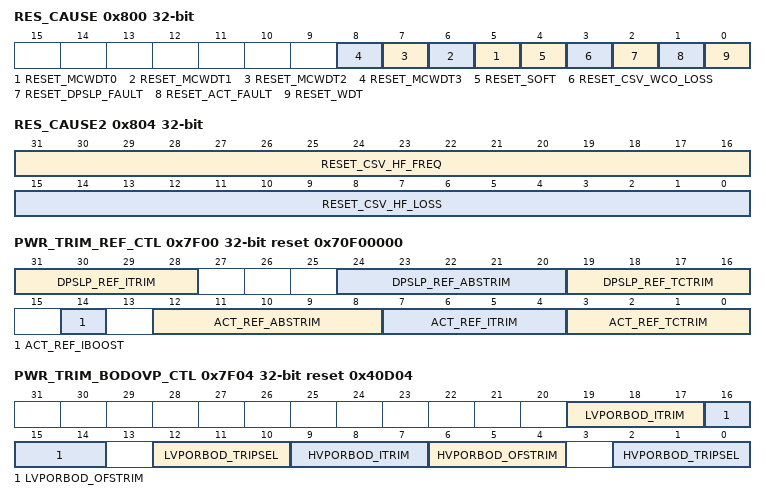
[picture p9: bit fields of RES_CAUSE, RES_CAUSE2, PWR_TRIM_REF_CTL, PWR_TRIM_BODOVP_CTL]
0x800 RES_CAUSE — Reset Cause Observation Register
  [n+5] RESET_MCWDT{n} (n=0..3) — Multi-Counter Watchdog timer reset #{n} has occurred since last power cycle.
  [4] RESET_SOFT — A CPU requested a system reset through it's SYSRESETREQ. This can be done via a debugger probe or in firmware.
  [3] RESET_CSV_WCO_LOSS — Clock supervision logic requested a reset due to loss of a watch-crystal clock.
  [2] RESET_DPSLP_FAULT — Fault logging system requested a reset from its DeepSleep logic.
  [1] RESET_ACT_FAULT — Fault logging system requested a reset from its Active logic.
  [0] RESET_WDT — A basic WatchDog Timer (WDT) reset has occurred since last power cycle.
0x804 RES_CAUSE2 — Reset Cause Observation Register 2
  [31:16] RESET_CSV_HF_FREQ — Clock supervision logic requested a reset due to frequency error of high-frequency clock. Each bit index K corresponds to a HFCLK<K>. Unimplemented clock bits return zero.
  [15:0] RESET_CSV_HF_LOSS — Clock supervision logic requested a reset due to loss of a high-frequency clock. Each bit index K corresponds to a HFCLK<K>. Unimplemented clock bits return zero.
0x7F00 PWR_TRIM_REF_CTL reset 0x70F00000 — Reference Trim Register
  [31:28] DPSLP_REF_ITRIM — DeepSleep current reference trim. This register is only reset by XRES/POR/BOD/OVP/HIBERNATE.
  [24:20] DPSLP_REF_ABSTRIM — DeepSleep-Reference absolute voltage trim. This register is only reset by XRES/POR/BOD/OVP/HIBERNATE.
  [19:16] DPSLP_REF_TCTRIM — DeepSleep-Reference temperature trim. This register is only reset by XRES/POR/BOD/OVP/HIBERNATE. 0 -> default setting at POR; not for trimming use others -> normal trim range
  [14] ACT_REF_IBOOST — Active-Reference current boost. This register is only reset by XRES/POR/BOD/OVP/HIBERNATE. 0: normal operation others: risk mitigation
  [12:8] ACT_REF_ABSTRIM — Active-Reference absolute voltage trim. This register is only reset by XRES/POR/BOD/OVP/HIBERNATE. 0 -> default setting at POR; not for trimming use others -> normal trim range
  [7:4] ACT_REF_ITRIM — Active-Reference current trim. This register is only reset by XRES/POR/BOD/OVP/HIBERNATE. 0 -> default setting at POR; not for trimming use others -> normal trim range
  [3:0] ACT_REF_TCTRIM — Active-Reference temperature trim. This register is only reset by XRES/POR/BOD/OVP/HIBERNATE. 0 -> default setting at POR; not for trimming use others -> normal trim range
0x7F04 PWR_TRIM_BODOVP_CTL reset 0x40D04 — BOD/OVP Trim Register
  [19:17] LVPORBOD_ITRIM — LVPORBOD current trim. This register is only reset by XRES/POR/BOD/OVP/HIBERNATE.
  [16:14] LVPORBOD_OFSTRIM — LVPORBOD offset trim. This register is only reset by XRES/POR/BOD/OVP/HIBERNATE.
  [12:10] LVPORBOD_TRIPSEL — LVPORBOD trip point selection. Monitors vccd. This register is only reset by XRES/POR/BOD/OVP/HIBERNATE.
  [9:7] HVPORBOD_ITRIM — HVPORBOD current trim. This register is only reset by XRES/POR/BOD/OVP/HIBERNATE.
  [6:4] HVPORBOD_OFSTRIM — HVPORBOD offset trim. This register is only reset by XRES/POR/BOD/OVP/HIBERNATE.
  [2:0] HVPORBOD_TRIPSEL — HVPORBOD trip point selection. Monitors vddd. This register is only reset by XRES/POR/BOD/OVP/HIBERNATE.
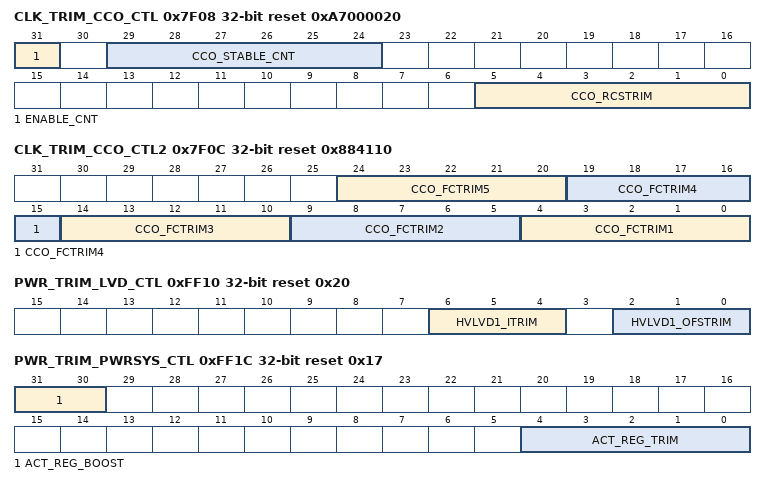
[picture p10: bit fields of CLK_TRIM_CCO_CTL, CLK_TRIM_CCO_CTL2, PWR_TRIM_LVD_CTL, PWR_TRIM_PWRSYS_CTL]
0x7F08 CLK_TRIM_CCO_CTL reset 0xA7000020 — CCO Trim Register
  [31] ENABLE_CNT — Enables the automatic stabilization counter.
  [29:24] CCO_STABLE_CNT — Terminal count for the stabilization counter from CCO_ENABLE until stable.
  [5:0] CCO_RCSTRIM — CCO reference current source trim.
0x7F0C CLK_TRIM_CCO_CTL2 reset 0x884110 — CCO Trim Register 2
  [24:20] CCO_FCTRIM5 — CCO frequency 5th range calibration
  [19:15] CCO_FCTRIM4 — CCO frequency 4th range calibration
  [14:10] CCO_FCTRIM3 — CCO frequency 3rd range calibration
  [9:5] CCO_FCTRIM2 — CCO frequency 2nd range calibration
  [4:0] CCO_FCTRIM1 — CCO frequency 1st range calibration
0x7F30 PWR_TRIM_WAKE_CTL — Wakeup Trim Register
  [7:0] WAKE_DELAY — Wakeup holdoff. Spec (fastest) wake time is achieve with a setting of 0. Additional delay can be added for debugging or workaround. The delay is counted by the IMO.
0xFF10 PWR_TRIM_LVD_CTL reset 0x20 — LVD Trim Register
  [6:4] HVLVD1_ITRIM — HVLVD1 current trim
  [2:0] HVLVD1_OFSTRIM — HVLVD1 offset trim
0xFF18 CLK_TRIM_ILO_CTL reset 0x2C — ILO Trim Register
  [5:0] ILO_FTRIM — ILO frequency trims. LSB step size is 1.5 percent (typical) of the frequency.
0xFF1C PWR_TRIM_PWRSYS_CTL reset 0x17 (reset mask 0x1F) — Power System Trim Register
  [31:30] ACT_REG_BOOST — Controls the tradeoff between output current and internal operating current for the Active Regulator. The maximum output current depends on the silicon implementation, but an application may limit its maximum current to less than that. This may allow a reduction in the internal operating current of the regulator. The regulator internal operating current depends on the boost setting: 2'b00: 50uA 2'b01: 100uA 2'b10: 150uA 2'b11: 200uA The allowed setting is a lookup table based on the chip-specific maximum (set in factory) and an application-specific maximum (set by customer). The defaults are set assuming the application consumes the maximum allowed by the chip. 50mA chip: 2'b00 (default); 100mA chip: 2'b00 (default); 150mA chip: 50..100mA app => 2'b00, 150mA app => 2'b01 (default); 200mA chip: 50mA app => 2'b00, 100..150mA app => 2'b01, 200mA app => 2'b10 (default); 250mA chip: 50mA app => 2'b00, 100..150mA app => 2'b01, 200..250mA app => 2'b10 (default); 300mA chip: 50mA app => 2'b00, 100..150mA app => 2'b01, 200..250mA app => 2'b10, 300mA app => 2'b11 (default); This register is only reset by XRES/POR/BOD/OVP/HIBERNATE.
  [4:0] ACT_REG_TRIM — Trim for the Active-Regulator. This sets the output voltage level. This register is only reset by XRES/POR/BOD/OVP/HIBERNATE. The nominal output voltage is vccd=812.5mV + ACT_REG_TRIM*12.5mV. The actual output voltage will vary depending on conditions and load. The following settings are explicitly shown for convenience, and other values may be calculated using the formula: 5'h07: 900mV (nominal) 5'h17: 1100mV (nominal)
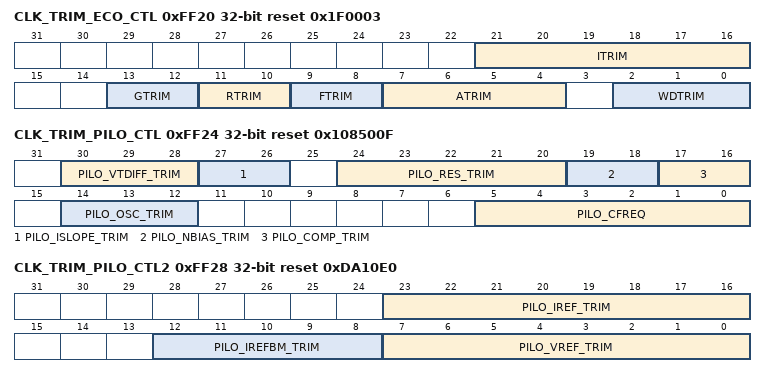
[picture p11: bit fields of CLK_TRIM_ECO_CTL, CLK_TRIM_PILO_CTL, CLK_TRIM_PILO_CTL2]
0xFF20 CLK_TRIM_ECO_CTL reset 0x1F0003 — ECO Trim Register
  [21:16] ITRIM — Current Trim
  [13:12] GTRIM — Gain Trim - Startup time
  [11:10] RTRIM — Feedback resistor Trim
  [9:8] FTRIM — Filter Trim - 3rd harmonic oscillation
  [7:4] ATRIM — Amplitude trim to set the crystal drive level when ECO_CONFIG.AGC_EN=1. WARNING: use care when setting this field because driving a crystal beyond its rated limit can permanently damage the crystal. 0x0 - 150mV 0x1 - 175mV 0x2 - 200mV 0x3 - 225mV 0x4 - 250mV 0x5 - 275mV 0x6 - 300mV 0x7 - 325mV 0x8 - 350mV 0x9 - 375mV 0xA - 400mV 0xB - 425mV 0xC - 450mV 0xD - 475mV 0xE - 500mV 0xF - 525mV
  [2:0] WDTRIM — Watch Dog Trim - Delta voltage below stead state level 0x0 - 50mV 0x1 - 75mV 0x2 - 100mV 0x3 - 125mV 0x4 - 150mV 0x5 - 175mV 0x6 - 200mV 0x7 - 225mV
0xFF24 CLK_TRIM_PILO_CTL reset 0x108500F — PILO Trim Register
  [30:28] PILO_VTDIFF_TRIM — Trim for VT-DIFF output (internal power supply)
  [27:26] PILO_ISLOPE_TRIM — Trim for beta-multiplier current slope
  [24:20] PILO_RES_TRIM — Trim for beta-multiplier branch current
  [19:18] PILO_NBIAS_TRIM — Trim for biasn by trimming sub-Vth NMOS width in beta-multiplier
  [17:16] PILO_COMP_TRIM — Trim for comparator bias current.
  [14:12] PILO_OSC_TRIM — Trim for current in oscillator block.
  [5:0] PILO_CFREQ — Coarse frequency trim to meet 32.768kHz +/-2 percent across PVT without calibration. The nominal step size of the LSB is 1kHz.
0xFF28 CLK_TRIM_PILO_CTL2 reset 0xDA10E0 — PILO Trim Register 2
  [23:16] PILO_IREF_TRIM — Trim for current reference
  [12:8] PILO_IREFBM_TRIM — Trim for beta-multiplier current reference
  [7:0] PILO_VREF_TRIM — Trim for voltage reference
0xFF2C CLK_TRIM_PILO_CTL3 reset 0x4800 — PILO Trim Register 3
  [15:0] PILO_ENGOPT — Engineering options for PILO circuits 0: Short vdda to vpwr 1: Beta:mult current change 2: Iref generation Ptat current addition 3: Disable current path in secondary Beta:mult startup circuit 4: Double oscillator current 5: Switch between deep:sub:threshold and sub:threshold stacks in Vref generation block 6: Spare 7: Ptat component increase in Iref 8: vpwr_rc and vpwr_dig_rc shorting testmode 9: Switch b/w psub connection for cascode nfet for vref generation 10: Switch between sub:threshold and deep:sub:threshold stacks in comparator. 15-11: Frequency fine trim. See AKK-444 for an overview of the trim strategy.
